# ing920 register map
Vendor: INGChips; Series: ing920xx; File version: 1.0
CPU: CM3 r2p1, little endian, no MPU, no FPU, 2 interrupt priority bits
Registers are 32-bit, read-write, reset 0x0 unless marked. A register's access mark holds for its fields unless they carry their own. Offsets are from the block's base; [hi:lo] are bit positions; {n}, {i} and the like mark numbered series.

## qdec
Base 0x40009000
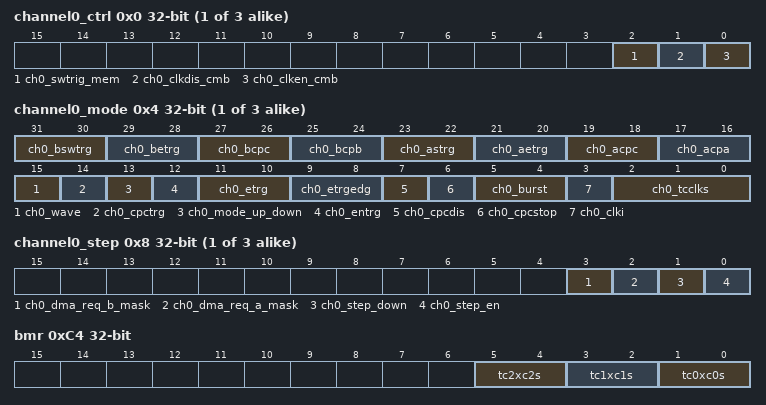
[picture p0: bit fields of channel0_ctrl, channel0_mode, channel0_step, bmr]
{0x0+0x40*i} channel{i}_ctrl (i=0..2) — reg description:
  [2] ch{i}_swtrig_mem — reg description:
  [1] ch{i}_clkdis_cmb — reg description:
  [0] ch{i}_clken_cmb — reg description:
{0x4+0x40*i} channel{i}_mode (i=0..2) — reg description:
  [31:30] ch{i}_bswtrg — reg description:
  [29:28] ch{i}_betrg — reg description:
  [27:26] ch{i}_bcpc — reg description:
  [25:24] ch{i}_bcpb — reg description:
  [23:22] ch{i}_astrg — reg description:
  [21:20] ch{i}_aetrg — reg description:
  [19:18] ch{i}_acpc — reg description:
  [17:16] ch{i}_acpa — reg description:
  [15] ch{i}_wave — reg description:
  [14] ch{i}_cpctrg — reg description:
  [13] ch{i}_mode_up_down — reg description:
  [12] ch{i}_entrg — reg description:
  [11:10] ch{i}_etrg — reg description:
  [9:8] ch{i}_etrgedg — reg description:
  [7] ch{i}_cpcdis — reg description:
  [6] ch{i}_cpcstop — reg description:
  [5:4] ch{i}_burst — reg description:
  [3] ch{i}_clki — reg description:
  [2:0] ch{i}_tcclks — reg description:
{0x8+0x40*i} channel{i}_step (i=0..2) — reg description:
  [3] ch{i}_dma_req_b_mask — reg description:
  [2] ch{i}_dma_req_a_mask — reg description:
  [1] ch{i}_step_down — reg description:
  [0] ch{i}_step_en — reg description:
{0xC+0x40*i} channel{i}_read_rab (i=0..2) — reg description:
  [15:0] ch{i}_tc_rab
{0x10+0x40*i} channel{i}_read_tc (i=0..2) — reg description:
  [15:0] ch{i}_tc_cv
{0x14+0x40*i} channel{i}write_a (i=0..2) — reg description:
  [15:0] ch{i}_tc_ra
{0x18+0x40*i} channel{i}write_b (i=0..2) — reg description:
  [15:0] ch{i}_tc_rb
{0x1C+0x40*i} channel{i}write_c (i=0..2) — reg description:
  [15:0] ch{i}_tc_rc
{0x20+0x40*i} channel{i}tiob0_rd (i=0..2) — reg description:
  [9:0] ch{i}_tc_sr
{0x24+0x40*i} channel{i}int_en (i=0..2) — reg description:
  [9:0] ch{i}_tc_imr_enable
{0x28+0x40*i} channel{i}int_dis (i=0..2) — reg description:
  [9:0] ch{i}_tc_imr_disable
{0x2C+0x40*i} channel{i}int_rd (i=0..2) — reg description:
  [9:0] ch{i}_tc_imr
0xC0 bcr — reg description:
  [0] bcr
0xC4 bmr — reg description:
  [5:4] tc2xc2s — reg description:
  [3:2] tc1xc1s — reg description:
  [1:0] tc0xc0s — reg description:
0xC8 qdec_inten — reg description:
  [3:0] qdec_int_en
0xCC qdec_intdis — reg description:
  [3:0] qdec_int_dis
0xD0 qdec_inten_rd — reg description:
  [3:0] qdec_int_mask
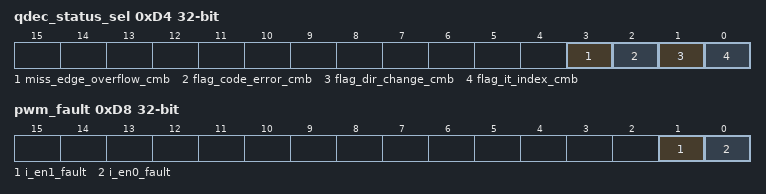
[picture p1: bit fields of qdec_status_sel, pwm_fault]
0xD4 qdec_status_sel — reg description:
  [3] miss_edge_overflow_cmb — reg description:
  [2] flag_code_error_cmb — reg description:
  [1] flag_dir_change_cmb — reg description:
  [0] flag_it_index_cmb — reg description:
0xD8 pwm_fault — reg description:
  [1] i_en1_fault — reg description:
  [0] i_en0_fault — reg description:
0xE0 dummy — reg description:
0xE4 wpmode — reg description:
  [0] wr_protected
0xEC addrsize — reg description:
0xF0 name1 — reg description:
0xF4 name2 — reg description:
0xF8 FEATURES — reg description:

## ptec
Base 0x40019000
{0x0+4i} REG_TASKS_CHG{i}_EN (i=0..3) — reg description:
  [0] tasks_chg{i}_en
{0x10+4i} REG_TASKS_CHG{i}_DIS (i=0..3) — reg description:
  [0] tasks_chg{i}_dis
{0x20+4i} REG_SUB_TASKS_CHG{i}_EN (i=0..3) — reg description:
  [7:0] sub_tasks_chg{i}_chidx
{0x30+4i} REG_SUB_TASKS_CHG{i}_DIS (i=0..3) — reg description:
  [7:0] sub_tasks_chg{i}_dis_chidx
0x100 REG_CHEN — reg description:
  [15:0] chen
0x104 REG_CHEN_set — reg description:
  [15:0] chen_set
0x108 REG_CHEN_clr — reg description:
  [15:0] chen_clr
{0x200+4i} REG_CHG{i}_MAP (i=0..3) — reg description:
  [15:0] chg{i}_map

## ingasdm
Base 0x4001A000
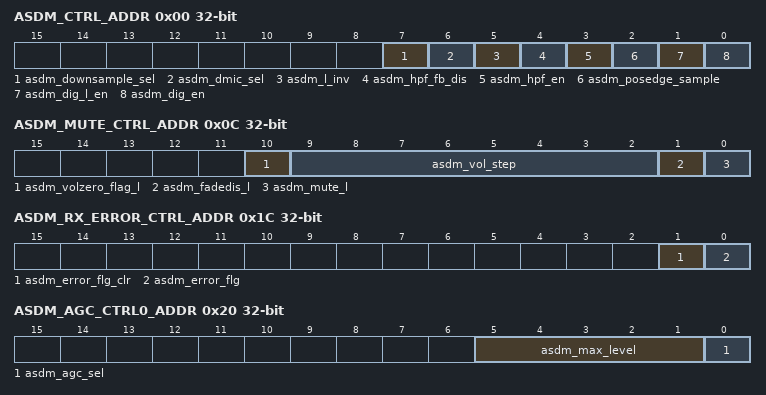
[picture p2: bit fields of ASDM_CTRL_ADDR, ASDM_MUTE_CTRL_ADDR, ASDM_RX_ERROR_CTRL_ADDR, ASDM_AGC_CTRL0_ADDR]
0x00 ASDM_CTRL_ADDR — reg description:
  [7] asdm_downsample_sel — reg description:
  [6] asdm_dmic_sel — reg description:
  [5] asdm_l_inv — reg description:
  [4] asdm_hpf_fb_dis — reg description:
  [3] asdm_hpf_en — reg description:
  [2] asdm_posedge_sample — reg description:
  [1] asdm_dig_l_en — reg description:
  [0] asdm_dig_en — reg description:
0x04 ASDM_SR_ADDR — reg description:
  [8:0] asdm_sr
0x08 ASDM_CLR_ADDR — reg description:
  [0] asdm_clr
0x0C ASDM_MUTE_CTRL_ADDR — reg description:
  [10] asdm_volzero_flag_l — reg description:
  [9:2] asdm_vol_step — reg description:
  [1] asdm_fadedis_l — reg description:
  [0] asdm_mute_l — reg description:
0x10 ASDM_VOL_CTRL_ADDR — reg description:
  [13:0] asdm_vol_l
0x14 ASDM_DOUT_ADDR — reg description:
  [31:0] asdm_dout
0x18 ASDM_HPF_COEF_ADDR — reg description:
  [11:0] asdm_hpf_coef
0x1C ASDM_RX_ERROR_CTRL_ADDR — reg description:
  [1] asdm_error_flg_clr — reg description:
  [0] asdm_error_flg — reg description:
0x20 ASDM_AGC_CTRL0_ADDR — reg description:
  [5:1] asdm_max_level — reg description:
  [0] asdm_agc_sel — reg description:
0x24 ASDM_AGC_CTRL1_ADDR — reg description:
  [11:0] asdm_frame_time
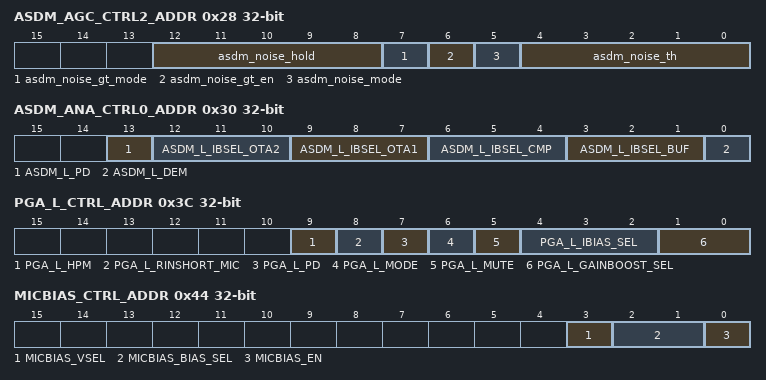
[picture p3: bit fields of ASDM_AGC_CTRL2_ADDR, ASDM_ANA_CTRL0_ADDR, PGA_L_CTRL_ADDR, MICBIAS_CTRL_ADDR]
0x28 ASDM_AGC_CTRL2_ADDR — reg description:
  [12:8] asdm_noise_hold — reg description:
  [7] asdm_noise_gt_mode — reg description:
  [6] asdm_noise_gt_en — reg description:
  [5] asdm_noise_mode — reg description:
  [4:0] asdm_noise_th — reg description:
0x2C ASDM_AGC_ST_ADDR — reg description:
  [0] asdm_agc_mute
0x30 ASDM_ANA_CTRL0_ADDR — reg description:
  [13] ASDM_L_PD — reg description:
  [12:10] ASDM_L_IBSEL_OTA2 — reg description:
  [9:7] ASDM_L_IBSEL_OTA1 — reg description:
  [6:4] ASDM_L_IBSEL_CMP — reg description:
  [3:1] ASDM_L_IBSEL_BUF — reg description:
  [0] ASDM_L_DEM — reg description:
0x34 ASDM_PGA_EN_IBIAS_ADDR — reg description:
  [0] ASDM_PGA_EN_IBIAS
0x3C PGA_L_CTRL_ADDR — reg description:
  [9] PGA_L_HPM — reg description:
  [8] PGA_L_RINSHORT_MIC — reg description:
  [7] PGA_L_PD — reg description:
  [6] PGA_L_MODE — reg description:
  [5] PGA_L_MUTE — reg description:
  [4:2] PGA_L_IBIAS_SEL — reg description:
  [1:0] PGA_L_GAINBOOST_SEL — reg description:
0x40 PGA_L_VOL_CTRL_ADDR — reg description:
  [5:0] PGA_L_VOL_MIC
0x44 MICBIAS_CTRL_ADDR — reg description:
  [3] MICBIAS_VSEL — reg description:
  [2:1] MICBIAS_BIAS_SEL — reg description:
  [0] MICBIAS_EN — reg description:
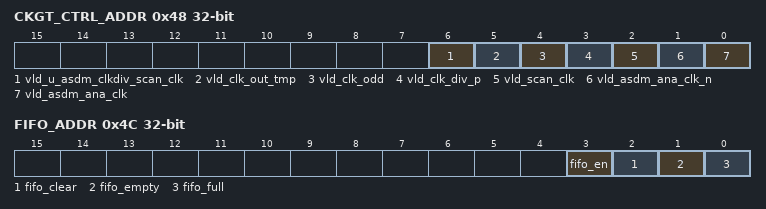
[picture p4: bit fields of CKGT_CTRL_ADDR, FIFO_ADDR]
0x48 CKGT_CTRL_ADDR — reg description:
  [6] vld_u_asdm_clkdiv_scan_clk — reg description:
  [5] vld_clk_out_tmp — reg description:
  [4] vld_clk_odd — reg description:
  [3] vld_clk_div_p — reg description:
  [2] vld_scan_clk — reg description:
  [1] vld_asdm_ana_clk_n — reg description:
  [0] vld_asdm_ana_clk — reg description:
0x4C FIFO_ADDR — reg description:
  [3] fifo_en — reg description:
  [2] fifo_clear — reg description:
  [1] fifo_empty — reg description:
  [0] fifo_full — reg description:
